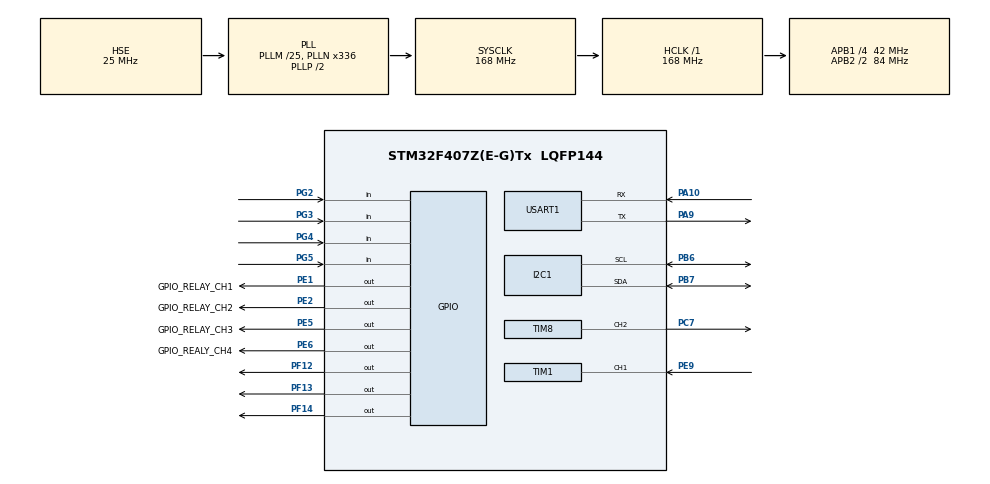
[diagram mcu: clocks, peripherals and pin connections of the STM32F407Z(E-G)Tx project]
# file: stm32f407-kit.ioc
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Dma.Request0=USART1_RX
Dma.Request1=TIM8_CH2
Dma.Request2=TIM1_CH1
Dma.TIM1_CH1.2.Direction=DMA_PERIPH_TO_MEMORY
Dma.TIM1_CH1.2.FIFOMode=DMA_FIFOMODE_DISABLE
Dma.TIM1_CH1.2.Instance=DMA2_Stream1
Dma.TIM1_CH1.2.MemDataAlignment=DMA_MDATAALIGN_HALFWORD
Dma.TIM1_CH1.2.MemInc=DMA_MINC_ENABLE
Dma.TIM1_CH1.2.Mode=DMA_CIRCULAR
Dma.TIM1_CH1.2.PeriphDataAlignment=DMA_PDATAALIGN_HALFWORD
Dma.TIM1_CH1.2.PeriphInc=DMA_PINC_DISABLE
Dma.TIM1_CH1.2.Priority=DMA_PRIORITY_LOW
Dma.TIM8_CH2.1.Direction=DMA_MEMORY_TO_PERIPH
Dma.TIM8_CH2.1.FIFOMode=DMA_FIFOMODE_DISABLE
Dma.TIM8_CH2.1.Instance=DMA2_Stream3
Dma.TIM8_CH2.1.MemDataAlignment=DMA_MDATAALIGN_HALFWORD
Dma.TIM8_CH2.1.MemInc=DMA_MINC_ENABLE
Dma.TIM8_CH2.1.Mode=DMA_NORMAL
Dma.TIM8_CH2.1.PeriphDataAlignment=DMA_PDATAALIGN_HALFWORD
Dma.TIM8_CH2.1.PeriphInc=DMA_PINC_DISABLE
Dma.TIM8_CH2.1.Priority=DMA_PRIORITY_LOW
Dma.USART1_RX.0.Direction=DMA_PERIPH_TO_MEMORY
Dma.USART1_RX.0.FIFOMode=DMA_FIFOMODE_DISABLE
Dma.USART1_RX.0.Instance=DMA2_Stream2
Dma.USART1_RX.0.MemDataAlignment=DMA_MDATAALIGN_BYTE
Dma.USART1_RX.0.MemInc=DMA_MINC_ENABLE
Dma.USART1_RX.0.Mode=DMA_CIRCULAR
Dma.USART1_RX.0.PeriphDataAlignment=DMA_PDATAALIGN_BYTE
Dma.USART1_RX.0.PeriphInc=DMA_PINC_DISABLE
Dma.USART1_RX.0.Priority=DMA_PRIORITY_LOW
FREERTOS.Mutexes01=log_mutex,Dynamic,NULL,Available
FREERTOS.Queues01=event_queue,16,event_msg_t,0,Dynamic,NULL,NULL
FREERTOS.Tasks01=defaultTask,24,512,StartDefaultTask,Default,NULL,Dynamic,NULL,NULL;cli_thread,24,256,cliThread,As external,NULL,Dynamic,NULL,NULL;neoxpixel_threa,24,256,neopixelThread,As external,NULL,Dynamic,NULL,NULL;event_thread,24,256,eventThread,As external,NULL,Dynamic,NULL,NULL;system_thread,24,256,systemThread,As external,NULL,Dynamic,NULL,NULL;relay_thread,24,256,relayThread,As external,NULL,Dynamic,NULL,NULL
FREERTOS.configCHECK_FOR_STACK_OVERFLOW=2
FREERTOS.configENABLE_FPU=1
FREERTOS.configTOTAL_HEAP_SIZE=48000
FREERTOS.configUSE_MALLOC_FAILED_HOOK=1
FREERTOS.configUSE_NEWLIB_REENTRANT=1
I2C1.I2C_Mode=I2C_Fast
Mcu.Family=STM32F4
Mcu.Name=STM32F407Z(E-G)Tx
Mcu.Package=LQFP144
NVIC.DMA2_Stream1_IRQn=true\:5\:0\:false\:false\:true\:true\:true\:true\:true
NVIC.DMA2_Stream3_IRQn=true\:5\:0\:false\:false\:true\:true\:true\:true\:true
NVIC.PriorityGroup=NVIC_PRIORITYGROUP_4
NVIC.TIM7_IRQn=true\:15\:0\:false\:false\:true\:false\:false\:true\:true
NVIC.TimeBase=TIM7_IRQn
NVIC.TimeBaseIP=TIM7
PA10.Mode=Asynchronous
PA10.Signal=USART1_RX
PA13.Mode=Serial_Wire
PA13.Signal=SYS_JTMS-SWDIO
PA14.Mode=Serial_Wire
PA14.Signal=SYS_JTCK-SWCLK
PA9.Mode=Asynchronous
PA9.Signal=USART1_TX
PB6.Mode=I2C
PB6.Signal=I2C1_SCL
PB7.Mode=I2C
PB7.Signal=I2C1_SDA
PC14-OSC32_IN.Mode=LSE-External-Oscillator
PC14-OSC32_IN.Signal=RCC_OSC32_IN
PC15-OSC32_OUT.Mode=LSE-External-Oscillator
PC15-OSC32_OUT.Signal=RCC_OSC32_OUT
PC7.GPIO_Speed=GPIO_SPEED_FREQ_VERY_HIGH
PC7.Signal=S_TIM8_CH2
PE1.GPIO_Label=GPIO_RELAY_CH1
PE1.PinState=GPIO_PIN_RESET
PE1.Signal=GPIO_Output
PE2.GPIO_Label=GPIO_RELAY_CH2
PE2.PinState=GPIO_PIN_RESET
PE2.Signal=GPIO_Output
PE5.GPIO_Label=GPIO_RELAY_CH3
PE5.PinState=GPIO_PIN_RESET
PE5.Signal=GPIO_Output
PE6.GPIO_Label=GPIO_REALY_CH4
PE6.PinState=GPIO_PIN_RESET
PE6.Signal=GPIO_Output
PE9.Signal=S_TIM1_CH1
PF12.PinState=GPIO_PIN_SET
PF12.Signal=GPIO_Output
PF13.PinState=GPIO_PIN_SET
PF13.Signal=GPIO_Output
PF14.PinState=GPIO_PIN_SET
PF14.Signal=GPIO_Output
PG2.GPIO_PuPd=GPIO_PULLUP
PG2.Signal=GPIO_Input
PG3.GPIO_PuPd=GPIO_PULLUP
PG3.Signal=GPIO_Input
PG4.GPIO_PuPd=GPIO_PULLUP
PG4.Signal=GPIO_Input
PG5.GPIO_PuPd=GPIO_PULLUP
PG5.Signal=GPIO_Input
PH0-OSC_IN.Mode=HSE-External-Oscillator
PH0-OSC_IN.Signal=RCC_OSC_IN
PH1-OSC_OUT.Mode=HSE-External-Oscillator
PH1-OSC_OUT.Signal=RCC_OSC_OUT
ProjectManager.HeapSize=0x200
ProjectManager.StackSize=0x400
ProjectManager.TargetToolchain=CMake
RCC.48MHZClocksFreq_Value=84000000
RCC.AHBFreq_Value=168000000
RCC.APB1CLKDivider=RCC_HCLK_DIV4
RCC.APB1Freq_Value=42000000
RCC.APB1TimFreq_Value=84000000
RCC.APB2CLKDivider=RCC_HCLK_DIV2
RCC.APB2Freq_Value=84000000
RCC.APB2TimFreq_Value=168000000
RCC.CortexFreq_Value=168000000
RCC.HCLKFreq_Value=168000000
RCC.HSE_VALUE=25000000
RCC.HSI_VALUE=16000000
RCC.PLLM=25
RCC.PLLN=336
RCC.PLLSourceVirtual=RCC_PLLSOURCE_HSE
RCC.SYSCLKFreq_VALUE=168000000
RCC.SYSCLKSource=RCC_SYSCLKSOURCE_PLLCLK
RCC.VCOOutputFreq_Value=336000000
SH.S_TIM1_CH1.0=TIM1_CH1,Input_Capture1_from_TI1
SH.S_TIM1_CH1.1=TIM1_CH1,TriggerSource_TI1FP1
SH.S_TIM8_CH2.0=TIM8_CH2,PWM Generation2 CH2
TIM1.Channel-Input_Capture1_from_TI1=TIM_CHANNEL_1
TIM1.ICFilter_CH1=8
TIM1.ICPolarity_CH1=TIM_INPUTCHANNELPOLARITY_BOTHEDGE
TIM1.Prescaler=167
TIM8.Channel-PWM\ Generation2\ CH2=TIM_CHANNEL_2
TIM8.Period=217
USART1.VirtualMode=VM_ASYNC
VP_FREERTOS_VS_CMSIS_V2.Mode=CMSIS_V2
VP_SYS_VS_tim7.Mode=TIM7
VP_TIM1_VS_ClockSourceINT.Mode=Internal
VP_TIM1_VS_ControllerModeReset.Mode=Reset Mode
VP_TIM8_VS_ClockSourceINT.Mode=Internal
board=custom

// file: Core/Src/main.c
/* USER CODE BEGIN Header */
/**
  ******************************************************************************
  * @file           : main.c
  * @brief          : Main program body
  ******************************************************************************
  * @attention
  *
  * Copyright (c) 2025 STMicroelectronics.
  * All rights reserved.
  *
  * This software is licensed under terms that can be found in the LICENSE file
  * in the root directory of this software component.
  * If no LICENSE file comes with this software, it is provided AS-IS.
  *
  ******************************************************************************
  */
/* USER CODE END Header */
#include "main.h"
#include "cmsis_os.h"

/* USER CODE BEGIN Includes */
#include "ap.h"
/* USER CODE END Includes */

I2C_HandleTypeDef hi2c1;

TIM_HandleTypeDef htim1;
TIM_HandleTypeDef htim8;
DMA_HandleTypeDef hdma_tim1_ch1;
DMA_HandleTypeDef hdma_tim8_ch2;

UART_HandleTypeDef huart1;
DMA_HandleTypeDef hdma_usart1_rx;

/* Definitions for defaultTask */
osThreadId_t defaultTaskHandle;
const osThreadAttr_t defaultTask_attributes = {
  .name = "defaultTask",
  .stack_size = 512 * 4,
  .priority = (osPriority_t) osPriorityNormal,
};
/* Definitions for cli_thread */
osThreadId_t cli_threadHandle;
const osThreadAttr_t cli_thread_attributes = {
  .name = "cli_thread",
  .stack_size = 256 * 4,
  .priority = (osPriority_t) osPriorityNormal,
};
/* Definitions for neoxpixel_threa */
osThreadId_t neoxpixel_threaHandle;
const osThreadAttr_t neoxpixel_threa_attributes = {
  .name = "neoxpixel_threa",
  .stack_size = 256 * 4,
  .priority = (osPriority_t) osPriorityNormal,
};
/* Definitions for event_thread */
osThreadId_t event_threadHandle;
const osThreadAttr_t event_thread_attributes = {
  .name = "event_thread",
  .stack_size = 256 * 4,
  .priority = (osPriority_t) osPriorityNormal,
};
/* Definitions for system_thread */
osThreadId_t system_threadHandle;
const osThreadAttr_t system_thread_attributes = {
  .name = "system_thread",
  .stack_size = 256 * 4,
  .priority = (osPriority_t) osPriorityNormal,
};
/* Definitions for relay_thread */
osThreadId_t relay_threadHandle;
const osThreadAttr_t relay_thread_attributes = {
  .name = "relay_thread",
  .stack_size = 256 * 4,
  .priority = (osPriority_t) osPriorityNormal,
};
/* Definitions for event_queue */
osMessageQueueId_t event_queueHandle;
const osMessageQueueAttr_t event_queue_attributes = {
  .name = "event_queue"
};
/* Definitions for log_mutex */
osMutexId_t log_mutexHandle;
const osMutexAttr_t log_mutex_attributes = {
  .name = "log_mutex"
};

void SystemClock_Config(void);
static void MX_GPIO_Init(void);
static void MX_DMA_Init(void);
static void MX_USART1_UART_Init(void);
static void MX_I2C1_Init(void);
static void MX_TIM8_Init(void);
static void MX_TIM1_Init(void);
void StartDefaultTask(void *argument);
extern void cliThread(void *argument);
extern void neopixelThread(void *argument);
extern void eventThread(void *argument);
extern void systemThread(void *argument);
extern void relayThread(void *argument);

int main(void)
{

  /* MCU Configuration--------------------------------------------------------*/

  /* Reset of all peripherals, Initializes the Flash interface and the Systick. */
  HAL_Init();

  /* Configure the system clock */
  SystemClock_Config();

  /* Initialize all configured peripherals */
  MX_GPIO_Init();
  MX_DMA_Init();
  MX_USART1_UART_Init();
  MX_I2C1_Init();
  MX_TIM8_Init();
  MX_TIM1_Init();
  /* USER CODE BEGIN 2 */

  hwInit();
  apInit();

  /* USER CODE END 2 */

  /* Init scheduler */
  osKernelInitialize();
  /* Create the mutex(es) */
  /* creation of log_mutex */
  log_mutexHandle = osMutexNew(&log_mutex_attributes);

  /* Create the queue(s) */
  /* creation of event_queue */
  event_queueHandle = osMessageQueueNew (16, sizeof(event_msg_t), &event_queue_attributes);

  /* Create the thread(s) */
  /* creation of defaultTask */
  defaultTaskHandle = osThreadNew(StartDefaultTask, NULL, &defaultTask_attributes);

  /* creation of cli_thread */
  cli_threadHandle = osThreadNew(cliThread, NULL, &cli_thread_attributes);

  /* creation of neoxpixel_threa */
  neoxpixel_threaHandle = osThreadNew(neopixelThread, NULL, &neoxpixel_threa_attributes);

  /* creation of event_thread */
  event_threadHandle = osThreadNew(eventThread, NULL, &event_thread_attributes);

  /* creation of system_thread */
  system_threadHandle = osThreadNew(systemThread, NULL, &system_thread_attributes);

  /* creation of relay_thread */
  relay_threadHandle = osThreadNew(relayThread, NULL, &relay_thread_attributes);

  /* Start scheduler */
  osKernelStart();

  /* We should never get here as control is now taken by the scheduler */

  /* Infinite loop */
  while (1)
  {

  }
}

void SystemClock_Config(void)
{
  RCC_OscInitTypeDef RCC_OscInitStruct = {0};
  RCC_ClkInitTypeDef RCC_ClkInitStruct = {0};

  /** Configure the main internal regulator output voltage
  */
  __HAL_RCC_PWR_CLK_ENABLE();
  __HAL_PWR_VOLTAGESCALING_CONFIG(PWR_REGULATOR_VOLTAGE_SCALE1);

  /** Initializes the RCC Oscillators according to the specified parameters
  * in the RCC_OscInitTypeDef structure.
  */
  RCC_OscInitStruct.OscillatorType = RCC_OSCILLATORTYPE_HSE;
  RCC_OscInitStruct.HSEState = RCC_HSE_ON;
  RCC_OscInitStruct.PLL.PLLState = RCC_PLL_ON;
  RCC_OscInitStruct.PLL.PLLSource = RCC_PLLSOURCE_HSE;
  RCC_OscInitStruct.PLL.PLLM = 25;
  RCC_OscInitStruct.PLL.PLLN = 336;
  RCC_OscInitStruct.PLL.PLLP = RCC_PLLP_DIV2;
  RCC_OscInitStruct.PLL.PLLQ = 4;
  if (HAL_RCC_OscConfig(&RCC_OscInitStruct) != HAL_OK)
  {
    Error_Handler();
  }

  /** Initializes the CPU, AHB and APB buses clocks
  */
  RCC_ClkInitStruct.ClockType = RCC_CLOCKTYPE_HCLK|RCC_CLOCKTYPE_SYSCLK
                              |RCC_CLOCKTYPE_PCLK1|RCC_CLOCKTYPE_PCLK2;
  RCC_ClkInitStruct.SYSCLKSource = RCC_SYSCLKSOURCE_PLLCLK;
  RCC_ClkInitStruct.AHBCLKDivider = RCC_SYSCLK_DIV1;
  RCC_ClkInitStruct.APB1CLKDivider = RCC_HCLK_DIV4;
  RCC_ClkInitStruct.APB2CLKDivider = RCC_HCLK_DIV2;

  if (HAL_RCC_ClockConfig(&RCC_ClkInitStruct, FLASH_LATENCY_5) != HAL_OK)
  {
    Error_Handler();
  }
}

static void MX_I2C1_Init(void)
{

  hi2c1.Instance = I2C1;
  hi2c1.Init.ClockSpeed = 400000;
  hi2c1.Init.DutyCycle = I2C_DUTYCYCLE_2;
  hi2c1.Init.OwnAddress1 = 0;
  hi2c1.Init.AddressingMode = I2C_ADDRESSINGMODE_7BIT;
  hi2c1.Init.DualAddressMode = I2C_DUALADDRESS_DISABLE;
  hi2c1.Init.OwnAddress2 = 0;
  hi2c1.Init.GeneralCallMode = I2C_GENERALCALL_DISABLE;
  hi2c1.Init.NoStretchMode = I2C_NOSTRETCH_DISABLE;
  if (HAL_I2C_Init(&hi2c1) != HAL_OK)
  {
    Error_Handler();
  }

}

static void MX_TIM1_Init(void)
{

  TIM_ClockConfigTypeDef sClockSourceConfig = {0};
  TIM_SlaveConfigTypeDef sSlaveConfig = {0};
  TIM_MasterConfigTypeDef sMasterConfig = {0};
  TIM_IC_InitTypeDef sConfigIC = {0};

  htim1.Instance = TIM1;
  htim1.Init.Prescaler = 167;
  htim1.Init.CounterMode = TIM_COUNTERMODE_UP;
  htim1.Init.Period = 65535;
  htim1.Init.ClockDivision = TIM_CLOCKDIVISION_DIV1;
  htim1.Init.RepetitionCounter = 0;
  htim1.Init.AutoReloadPreload = TIM_AUTORELOAD_PRELOAD_DISABLE;
  if (HAL_TIM_Base_Init(&htim1) != HAL_OK)
  {
    Error_Handler();
  }
  sClockSourceConfig.ClockSource = TIM_CLOCKSOURCE_INTERNAL;
  if (HAL_TIM_ConfigClockSource(&htim1, &sClockSourceConfig) != HAL_OK)
  {
    Error_Handler();
  }
  if (HAL_TIM_IC_Init(&htim1) != HAL_OK)
  {
    Error_Handler();
  }
  sSlaveConfig.SlaveMode = TIM_SLAVEMODE_RESET;
  sSlaveConfig.InputTrigger = TIM_TS_TI1FP1;
  sSlaveConfig.TriggerPolarity = TIM_INPUTCHANNELPOLARITY_BOTHEDGE;
  sSlaveConfig.TriggerFilter = 0;
  if (HAL_TIM_SlaveConfigSynchro(&htim1, &sSlaveConfig) != HAL_OK)
  {
    Error_Handler();
  }
  sMasterConfig.MasterOutputTrigger = TIM_TRGO_RESET;
  sMasterConfig.MasterSlaveMode = TIM_MASTERSLAVEMODE_DISABLE;
  if (HAL_TIMEx_MasterConfigSynchronization(&htim1, &sMasterConfig) != HAL_OK)
  {
    Error_Handler();
  }
  sConfigIC.ICPolarity = TIM_INPUTCHANNELPOLARITY_BOTHEDGE;
  sConfigIC.ICSelection = TIM_ICSELECTION_DIRECTTI;
  sConfigIC.ICPrescaler = TIM_ICPSC_DIV1;
  sConfigIC.ICFilter = 8;
  if (HAL_TIM_IC_ConfigChannel(&htim1, &sConfigIC, TIM_CHANNEL_1) != HAL_OK)
  {
    Error_Handler();
  }

}

static void MX_TIM8_Init(void)
{

  TIM_ClockConfigTypeDef sClockSourceConfig = {0};
  TIM_MasterConfigTypeDef sMasterConfig = {0};
  TIM_OC_InitTypeDef sConfigOC = {0};
  TIM_BreakDeadTimeConfigTypeDef sBreakDeadTimeConfig = {0};

  htim8.Instance = TIM8;
  htim8.Init.Prescaler = 0;
  htim8.Init.CounterMode = TIM_COUNTERMODE_UP;
  htim8.Init.Period = 217;
  htim8.Init.ClockDivision = TIM_CLOCKDIVISION_DIV1;
  htim8.Init.RepetitionCounter = 0;
  htim8.Init.AutoReloadPreload = TIM_AUTORELOAD_PRELOAD_DISABLE;
  if (HAL_TIM_Base_Init(&htim8) != HAL_OK)
  {
    Error_Handler();
  }
  sClockSourceConfig.ClockSource = TIM_CLOCKSOURCE_INTERNAL;
  if (HAL_TIM_ConfigClockSource(&htim8, &sClockSourceConfig) != HAL_OK)
  {
    Error_Handler();
  }
  if (HAL_TIM_PWM_Init(&htim8) != HAL_OK)
  {
    Error_Handler();
  }
  sMasterConfig.MasterOutputTrigger = TIM_TRGO_RESET;
  sMasterConfig.MasterSlaveMode = TIM_MASTERSLAVEMODE_DISABLE;
  if (HAL_TIMEx_MasterConfigSynchronization(&htim8, &sMasterConfig) != HAL_OK)
  {
    Error_Handler();
  }
  sConfigOC.OCMode = TIM_OCMODE_PWM1;
  sConfigOC.Pulse = 0;
  sConfigOC.OCPolarity = TIM_OCPOLARITY_HIGH;
  sConfigOC.OCNPolarity = TIM_OCNPOLARITY_HIGH;
  sConfigOC.OCFastMode = TIM_OCFAST_DISABLE;
  sConfigOC.OCIdleState = TIM_OCIDLESTATE_RESET;
  sConfigOC.OCNIdleState = TIM_OCNIDLESTATE_RESET;
  if (HAL_TIM_PWM_ConfigChannel(&htim8, &sConfigOC, TIM_CHANNEL_2) != HAL_OK)
  {
    Error_Handler();
  }
  sBreakDeadTimeConfig.OffStateRunMode = TIM_OSSR_DISABLE;
  sBreakDeadTimeConfig.OffStateIDLEMode = TIM_OSSI_DISABLE;
  sBreakDeadTimeConfig.LockLevel = TIM_LOCKLEVEL_OFF;
  sBreakDeadTimeConfig.DeadTime = 0;
  sBreakDeadTimeConfig.BreakState = TIM_BREAK_DISABLE;
  sBreakDeadTimeConfig.BreakPolarity = TIM_BREAKPOLARITY_HIGH;
  sBreakDeadTimeConfig.AutomaticOutput = TIM_AUTOMATICOUTPUT_DISABLE;
  if (HAL_TIMEx_ConfigBreakDeadTime(&htim8, &sBreakDeadTimeConfig) != HAL_OK)
  {
    Error_Handler();
  }
  HAL_TIM_MspPostInit(&htim8);

}

static void MX_USART1_UART_Init(void)
{

  huart1.Instance = USART1;
  huart1.Init.BaudRate = 115200;
  huart1.Init.WordLength = UART_WORDLENGTH_8B;
  huart1.Init.StopBits = UART_STOPBITS_1;
  huart1.Init.Parity = UART_PARITY_NONE;
  huart1.Init.Mode = UART_MODE_TX_RX;
  huart1.Init.HwFlowCtl = UART_HWCONTROL_NONE;
  huart1.Init.OverSampling = UART_OVERSAMPLING_16;
  if (HAL_UART_Init(&huart1) != HAL_OK)
  {
    Error_Handler();
  }

}

static void MX_DMA_Init(void)
{

  /* DMA controller clock enable */
  __HAL_RCC_DMA2_CLK_ENABLE();

  /* DMA interrupt init */
  /* DMA2_Stream1_IRQn interrupt configuration */
  HAL_NVIC_SetPriority(DMA2_Stream1_IRQn, 5, 0);
  HAL_NVIC_EnableIRQ(DMA2_Stream1_IRQn);
  /* DMA2_Stream3_IRQn interrupt configuration */
  HAL_NVIC_SetPriority(DMA2_Stream3_IRQn, 5, 0);
  HAL_NVIC_EnableIRQ(DMA2_Stream3_IRQn);

}

static void MX_GPIO_Init(void)
{
  GPIO_InitTypeDef GPIO_InitStruct = {0};

  /* GPIO Ports Clock Enable */
  __HAL_RCC_GPIOE_CLK_ENABLE();
  __HAL_RCC_GPIOC_CLK_ENABLE();
  __HAL_RCC_GPIOH_CLK_ENABLE();
  __HAL_RCC_GPIOF_CLK_ENABLE();
  __HAL_RCC_GPIOG_CLK_ENABLE();
  __HAL_RCC_GPIOA_CLK_ENABLE();
  __HAL_RCC_GPIOB_CLK_ENABLE();

  /*Configure GPIO pin Output Level */
  HAL_GPIO_WritePin(GPIOE, GPIO_RELAY_CH2_Pin|GPIO_RELAY_CH3_Pin|GPIO_REALY_CH4_Pin|GPIO_RELAY_CH1_Pin, GPIO_PIN_RESET);

  /*Configure GPIO pin Output Level */
  HAL_GPIO_WritePin(GPIOF, GPIO_PIN_12|GPIO_PIN_13|GPIO_PIN_14, GPIO_PIN_SET);

  /*Configure GPIO pins : GPIO_RELAY_CH2_Pin GPIO_RELAY_CH3_Pin GPIO_REALY_CH4_Pin GPIO_RELAY_CH1_Pin */
  GPIO_InitStruct.Pin = GPIO_RELAY_CH2_Pin|GPIO_RELAY_CH3_Pin|GPIO_REALY_CH4_Pin|GPIO_RELAY_CH1_Pin;
  GPIO_InitStruct.Mode = GPIO_MODE_OUTPUT_PP;
  GPIO_InitStruct.Pull = GPIO_NOPULL;
  GPIO_InitStruct.Speed = GPIO_SPEED_FREQ_LOW;
  HAL_GPIO_Init(GPIOE, &GPIO_InitStruct);

  /*Configure GPIO pins : PF12 PF13 PF14 */
  GPIO_InitStruct.Pin = GPIO_PIN_12|GPIO_PIN_13|GPIO_PIN_14;
  GPIO_InitStruct.Mode = GPIO_MODE_OUTPUT_PP;
  GPIO_InitStruct.Pull = GPIO_NOPULL;
  GPIO_InitStruct.Speed = GPIO_SPEED_FREQ_LOW;
  HAL_GPIO_Init(GPIOF, &GPIO_InitStruct);

  /*Configure GPIO pins : PG2 PG3 PG4 PG5 */
  GPIO_InitStruct.Pin = GPIO_PIN_2|GPIO_PIN_3|GPIO_PIN_4|GPIO_PIN_5;
  GPIO_InitStruct.Mode = GPIO_MODE_INPUT;
  GPIO_InitStruct.Pull = GPIO_PULLUP;
  HAL_GPIO_Init(GPIOG, &GPIO_InitStruct);

}

void StartDefaultTask(void *argument)
{
  /* USER CODE BEGIN 5 */
  apMain();
  /* USER CODE END 5 */
}

void HAL_TIM_PeriodElapsedCallback(TIM_HandleTypeDef *htim)
{
  if (htim->Instance == TIM7)
  {
    HAL_IncTick();
  }
}

void Error_Handler(void)
{
  __disable_irq();
  while (1)
  {
  }
}
